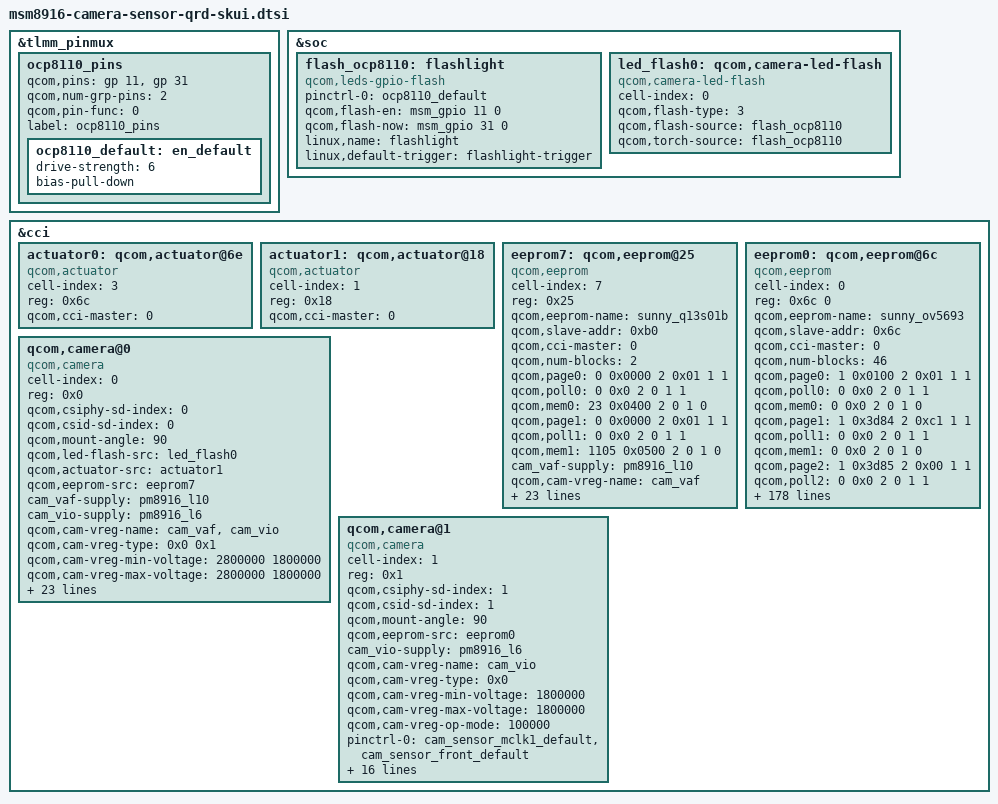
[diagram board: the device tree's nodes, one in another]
/*
 * Copyright (c) 2014, The Linux Foundation. All rights reserved.
 * Copyright (C) 2016 XiaoMi, Inc.
 *
 * This program is free software; you can redistribute it and/or modify
 * it under the terms of the GNU General Public License version 2 and
 * only version 2 as published by the Free Software Foundation.
 *
 * This program is distributed in the hope that it will be useful,
 * but WITHOUT ANY WARRANTY; without even the implied warranty of
 * MERCHANTABILITY or FITNESS FOR A PARTICULAR PURPOSE.  See the
 * GNU General Public License for more details.
 */
&tlmm_pinmux {
	ocp8110_pins {
		qcom,pins = <&gp 11> ,<&gp 31>;
		qcom,num-grp-pins = <2>;
		qcom,pin-func = <0>;
		label = "ocp8110_pins";
		ocp8110_default: en_default {
			  drive-strength = <6>;
			  bias-pull-down;
		};
	};
};

&soc {

	flash_ocp8110:flashlight {
		compatible = "qcom,leds-gpio-flash";
		status = "okay";
		pinctrl-names = "ocp8110_default";
		pinctrl-0 = <&ocp8110_default>;
		qcom,flash-en = <&msm_gpio 11 0>;
		qcom,flash-now = <&msm_gpio 31 0>;
		linux,name = "flashlight";
		linux,default-trigger = "flashlight-trigger";
	};

	led_flash0: qcom,camera-led-flash {
		cell-index = <0>;
		compatible = "qcom,camera-led-flash";
		qcom,flash-type = <3>;
		qcom,flash-source = <&flash_ocp8110>;
		qcom,torch-source = <&flash_ocp8110>;
	};
};

&cci {

	actuator0: qcom,actuator@6e {
		cell-index = <3>;
		reg = <0x6c>;
		compatible = "qcom,actuator";
		qcom,cci-master = <0>;
	};

	actuator1: qcom,actuator@18 {
		cell-index = <1>;
		reg = <0x18>;
		compatible = "qcom,actuator";
		qcom,cci-master = <0>;
	};
	eeprom7: qcom,eeprom@25 {
		cell-index = <7>;
		reg = <0x25>;
		qcom,eeprom-name = "sunny_q13s01b";
		compatible = "qcom,eeprom";
		qcom,slave-addr = <0xb0>;
		qcom,cci-master = <0>;
		qcom,num-blocks = <2>;
		qcom,page0 = <0 0x0000 2 0x01 1 1>;
		qcom,poll0 = <0 0x0 2 0 1 1>;
		qcom,mem0 = <23 0x0400 2 0 1 0>;
		qcom,page1 = <0 0x0000 2 0x01 1 1>;
		qcom,poll1 = <0 0x0 2 0 1 1>;
		qcom,mem1 = <1105 0x0500 2 0 1 0>;

		cam_vaf-supply = <&pm8916_l10>;
		qcom,cam-vreg-name = "cam_vaf";
		qcom,cam-vreg-type = <0>;
		qcom,cam-vreg-min-voltage = <2800000>;
		qcom,cam-vreg-max-voltage = <2800000>;
		qcom,cam-vreg-op-mode = <100000>;
		pinctrl-names = "cam_default", "cam_suspend";
		pinctrl-0 = <&cam_sensor_mclk0_default &cam_sensor_rear_default>;
		pinctrl-1 = <&cam_sensor_mclk0_sleep &cam_sensor_rear_sleep>;
		qcom,gpio-no-mux = <0>;
		gpios = <&msm_gpio 26 0>,
	        	<&msm_gpio 10 0>; /*This is CAM_AF_PWDM for q13s01b*/
		qcom,gpio-standby = <1>;
		qcom,gpio-req-tbl-num = <0 1>;
		qcom,gpio-req-tbl-flags = <1 0>;
		qcom,gpio-req-tbl-label = "CAMIF_MCLK","CAM_AF_PWDM";

		qcom,cam-power-seq-type = "sensor_vreg", "sensor_clk","sensor_gpio";
		qcom,cam-power-seq-val = "cam_vaf", "sensor_cam_mclk","sensor_gpio_standby";
		qcom,cam-power-seq-cfg-val = <1 23880000 1>;
		qcom,cam-power-seq-delay = <1 5 10>;
		clocks = <&clock_gcc clk_mclk0_clk_src>,<&clock_gcc clk_gcc_camss_mclk0_clk>;
		clock-names = "cam_src_clk", "cam_clk";
	};

	eeprom0: qcom,eeprom@6c {
		cell-index = <0>;
		reg = <0x6c 0>;
		qcom,eeprom-name = "sunny_ov5693";
		compatible = "qcom,eeprom";
		qcom,slave-addr = <0x6c>;
		qcom,cci-master = <0>;
		qcom,num-blocks = <46>;

		qcom,page0 = <1 0x0100 2 0x01 1 1>;
		qcom,poll0 = <0 0x0 2 0 1 1>;
		qcom,mem0 = <0 0x0 2 0 1 0>;

		/*blank0*/
		/*blank1*/
		qcom,page1 = <1 0x3d84 2 0xc1 1 1>;
		qcom,poll1 = <0 0x0 2 0 1 1>;
		qcom,mem1 = <0 0x0 2 0 1 0>;
		qcom,page2 = <1 0x3d85 2 0x00 1 1>;
		qcom,poll2 = <0 0x0 2 0 1 1>;
		qcom,mem2 = <0 0x0 2 0 1 0>;
		qcom,page3 = <1 0x3d86 2 0x0f 1 1>;
		qcom,pageen3 = <1 0x3d81 2 0x01 1 5>;
		qcom,poll3 = <0 0x0 2 0 1 1>;
		qcom,mem3 = <16 0x3d00 2 0 1 0>;

		/*blank2*/
		qcom,page4 = <1 0x3d84 2 0xc2 1 1>;
		qcom,poll4 = <0 0x0 2 0 1 1>;
		qcom,mem4 = <0 0x0 2 0 1 0>;

		qcom,page5 = <1 0x3d85 2 0x00 1 1>;
		qcom,poll5 = <0 0x0 2 0 1 1>;
		qcom,mem5 = <0 0x0 2 0 1 0>;

		qcom,page6 = <1 0x3d86 2 0x0f 1 1>;
		qcom,pageen6 = <1 0x3d81 2 0x01 1 5>;
		qcom,poll6 = <0 0x0 2 0 1 1>;
		qcom,mem6 = <16 0x3d00 2 0 1 0>;

		/*blank3*/
		qcom,page7 = <1 0x3d84 2 0xc3 1 1>;
		qcom,poll7 = <0 0x0 2 0 1 1>;
		qcom,mem7 = <0 0x0 2 0 1 0>;

		qcom,page8 = <1 0x3d85 2 0x00 1 1>;
		qcom,poll8 = <0 0x0 2 0 1 1>;
		qcom,mem8 = <0 0x0 2 0 1 0>;

		qcom,page9 = <1 0x3d86 2 0x0f 1 1>;
		qcom,pageen9 = <1 0x3d81 2 0x01 1 5>;
		qcom,poll9 = <0 0x0 2 0 1 1>;
		qcom,mem9 = <16 0x3d00 2 0 1 0>;

		/*blank4*/
		qcom,page10 = <1 0x3d84 2 0xc4 1 1>;
		qcom,poll10 = <0 0x0 2 0 1 1>;
		qcom,mem10 = <0 0x0 2 0 1 0>;

		qcom,page11 = <1 0x3d85 2 0x00 1 1>;
		qcom,poll11 = <0 0x0 2 0 1 1>;
		qcom,mem11 = <0 0x0 2 0 1 0>;

		qcom,page12 = <1 0x3d86 2 0x0f 1 1>;
		qcom,pageen12 = <1 0x3d81 2 0x01 1 5>;
		qcom,poll12 = <0 0x0 2 0 1 1>;
		qcom,mem12 = <16 0x3d00 2 0 1 0>;

		/*blank5*/
		qcom,page13 = <1 0x3d84 2 0xc5 1 1>;
		qcom,poll13 = <0 0x0 2 0 1 1>;
		qcom,mem13 = <0 0x0 2 0 1 0>;

		qcom,page14 = <1 0x3d85 2 0x00 1 1>;
		qcom,poll14 = <0 0x0 2 0 1 1>;
		qcom,mem14 = <0 0x0 2 0 1 0>;

		qcom,page15 = <1 0x3d86 2 0x0f 1 1>;
		qcom,pageen15 = <1 0x3d81 2 0x01 1 5>;
		qcom,poll15 = <0 0x0 2 0 1 1>;
		qcom,mem15 = <16 0x3d00 2 0 1 0>;

		/*blank6*/
		qcom,page16 = <1 0x3d84 2 0xc6 1 1>;
		qcom,poll16 = <0 0x0 2 0 1 1>;
		qcom,mem16 = <0 0x0 2 0 1 0>;

		qcom,page17 = <1 0x3d85 2 0x00 1 1>;
		qcom,poll17 = <0 0x0 2 0 1 1>;
		qcom,mem17 = <0 0x0 2 0 1 0>;

		qcom,page18 = <1 0x3d86 2 0x0f 1 1>;
		qcom,pageen18 = <1 0x3d81 2 0x01 1 5>;
		qcom,poll18 = <0 0x0 2 0 1 1>;
		qcom,mem18 = <16 0x3d00 2 0 1 0>;

		/*blank7*/
		qcom,page19 = <1 0x3d84 2 0xc7 1 1>;
		qcom,poll19 = <0 0x0 2 0 1 1>;
		qcom,mem19 = <0 0x0 2 0 1 0>;

		qcom,page20 = <1 0x3d85 2 0x00 1 1>;
		qcom,poll20 = <0 0x0 2 0 1 1>;
		qcom,mem20 = <0 0x0 2 0 1 0>;

		qcom,page21 = <1 0x3d86 2 0x0e 1 1>;
		qcom,pageen21 = <1 0x3d81 2 0x01 1 5>;
		qcom,poll21 = <0 0x0 2 0 1 1>;
		qcom,mem21 = <16 0x3d00 2 0 1 0>;

		/*blank8*/
		qcom,page22 = <1 0x3d84 2 0xc8 1 1>;
		qcom,poll22 = <0 0x0 2 0 1 1>;
		qcom,mem22 = <0 0x0 2 0 1 0>;

		qcom,page23 = <1 0x3d85 2 0x00 1 1>;
		qcom,poll23 = <0 0x0 2 0 1 1>;
		qcom,mem23 = <0 0x0 2 0 1 0>;

		qcom,page24 = <1 0x3d86 2 0x0f 1 1>;
		qcom,pageen24 = <1 0x3d81 2 0x01 1 5>;
		qcom,poll24 = <0 0x0 2 0 1 1>;
		qcom,mem24 = <16 0x3d00 2 0 1 0>;

		/*blank9*/
		qcom,page25 = <1 0x3d84 2 0xc9 1 1>;
		qcom,poll25 = <0 0x0 2 0 1 1>;
		qcom,mem25 = <0 0x0 2 0 1 0>;

		qcom,page26 = <1 0x3d85 2 0x00 1 1>;
		qcom,poll26 = <0 0x0 2 0 1 1>;
		qcom,mem26 = <0 0x0 2 0 1 0>;

		qcom,page27 = <1 0x3d86 2 0x0f 1 1>;
		qcom,pageen27 = <1 0x3d81 2 0x01 1 5>;
		qcom,poll27 = <0 0x0 2 0 1 1>;
		qcom,mem27 = <16 0x3d00 2 0 1 0>;

		/*blank10*/
		qcom,page28 = <1 0x3d84 2 0xca 1 1>;
		qcom,poll28 = <0 0x0 2 0 1 1>;
		qcom,mem28 = <0 0x0 2 0 1 0>;

		qcom,page29 = <1 0x3d85 2 0x00 1 1>;
		qcom,poll29 = <0 0x0 2 0 1 1>;
		qcom,mem29 = <0 0x0 2 0 1 0>;

		qcom,page30 = <1 0x3d86 2 0x0f 1 1>;
		qcom,pageen30 = <1 0x3d81 2 0x01 1 5>;
		qcom,poll30 = <0 0x0 2 0 1 1>;
		qcom,mem30 = <16 0x3d00 2 0 1 0>;

		/*blank11*/
		qcom,page31 = <1 0x3d84 2 0xcb 1 1>;
		qcom,poll31 = <0 0x0 2 0 1 1>;
		qcom,mem31 = <0 0x0 2 0 1 0>;

		qcom,page32 = <1 0x3d85 2 0x00 1 1>;
		qcom,poll32 = <0 0x0 2 0 1 1>;
		qcom,mem32 = <0 0x0 2 0 1 0>;

		qcom,page33 = <1 0x3d86 2 0x0e 1 1>;
		qcom,pageen33 = <1 0x3d81 2 0x01 1 5>;
		qcom,poll33 = <0 0x0 2 0 1 1>;
		qcom,mem33 = <16 0x3d00 2 0 1 0>;

		/*blank12*/
		qcom,page34 = <1 0x3d84 2 0xcc 1 1>;
		qcom,poll34 = <0 0x0 2 0 1 1>;
		qcom,mem34 = <0 0x0 2 0 1 0>;

		qcom,page35 = <1 0x3d85 2 0x00 1 1>;
		qcom,poll35 = <0 0x0 2 0 1 1>;
		qcom,mem35 = <0 0x0 2 0 1 0>;

		qcom,page36 = <1 0x3d86 2 0x0f 1 1>;
		qcom,pageen36 = <1 0x3d81 2 0x01 1 5>;
		qcom,poll36 = <0 0x0 2 0 1 1>;
		qcom,mem36 = <16 0x3d00 2 0 1 0>;

		/*blank13*/
		qcom,page37 = <1 0x3d84 2 0xcd 1 1>;
		qcom,poll37 = <0 0x0 2 0 1 1>;
		qcom,mem37 = <0 0x0 2 0 1 0>;

		qcom,page38 = <1 0x3d85 2 0x00 1 1>;
		qcom,poll38 = <0 0x0 2 0 1 1>;
		qcom,mem38 = <0 0x0 2 0 1 0>;

		qcom,page39 = <1 0x3d86 2 0x0f 1 1>;
		qcom,pageen39 = <1 0x3d81 2 0x01 1 5>;
		qcom,poll39 = <0 0x0 2 0 1 1>;
		qcom,mem39 = <16 0x3d00 2 0 1 0>;

		/*blank14*/
		qcom,page40 = <1 0x3d84 2 0xce 1 1>;
		qcom,poll40 = <0 0x0 2 0 1 1>;
		qcom,mem40 = <0 0x0 2 0 1 0>;

		qcom,page41 = <1 0x3d85 2 0x00 1 1>;
		qcom,poll41 = <0 0x0 2 0 1 1>;
		qcom,mem41 = <0 0x0 2 0 1 0>;

		qcom,page42 = <1 0x3d86 2 0x0f 1 1>;
		qcom,pageen42 = <1 0x3d81 2 0x01 1 5>;
		qcom,poll42 = <0 0x0 2 0 1 1>;
		qcom,mem42 = <16 0x3d00 2 0 1 0>;

		/*blank15*/
		qcom,page43 = <1 0x3d84 2 0xcf 1 1>;
		qcom,poll43 = <0 0x0 2 0 1 1>;
		qcom,mem43 = <0 0x0 2 0 1 0>;

		qcom,page44 = <1 0x3d85 2 0x00 1 1>;
		qcom,poll44 = <0 0x0 2 0 1 1>;
		qcom,mem44 = <0 0x0 2 0 1 0>;

		qcom,page45 = <1 0x3d86 2 0x0e 1 1>;
		qcom,pageen45 = <1 0x3d81 2 0x01 1 5>;
		qcom,poll45 = <0 0x0 2 0 1 1>;
		qcom,mem45 = <16 0x3d00 2 0 1 0>;

		cam_vio-supply = <&pm8916_l6>;
		cam_vana-supply = <&pm8916_l10>;
		qcom,cam-vreg-name = "cam_vio", "cam_vana";
		qcom,cam-vreg-type = <0 0>;
		qcom,cam-vreg-min-voltage = <1800000 2800000>;
		qcom,cam-vreg-max-voltage = <1800000 2800000>;
		qcom,cam-vreg-op-mode = <180000 80000>;
		pinctrl-names = "cam_default", "cam_suspend";
		pinctrl-0 = <&cam_sensor_mclk1_default &cam_sensor_front_default>;
		pinctrl-1 = <&cam_sensor_mclk1_sleep &cam_sensor_front_sleep>;

		gpios = <&msm_gpio 22 0>,
			<&msm_gpio 27 0>,
			<&msm_gpio 28 0>,
			<&msm_gpio 33 0>,
			<&msm_gpio 120 0>;
		qcom,gpio-vana = <0>;
		qcom,gpio-reset = <2>;
		qcom,gpio-standby = <3>;
		qcom,gpio-vdig = <4>;
		qcom,gpio-req-tbl-num = <0 1 2 3 4>;
		qcom,gpio-req-tbl-flags = <0 1 0 0 0>;
		qcom,gpio-req-tbl-label = "CAM_VANA",
			"CAMIF_MCLK",
			"CAM_RESET",
			"CAM_STANDBY",
			"CAM_VDIG";

		qcom,cam-power-seq-type = "sensor_vreg","sensor_gpio","sensor_vreg","sensor_gpio",
			"sensor_gpio", "sensor_gpio" , "sensor_clk";

		qcom,cam-power-seq-val = "cam_vio","sensor_gpio_vana","cam_vana","sensor_gpio_vdig",
			"sensor_gpio_reset", "sensor_gpio_standby","sensor_cam_mclk";
		qcom,cam-power-seq-cfg-val = <1 1 1 1 1 1 23880000>;
		qcom,cam-power-seq-delay = <5 5 5 5 5 5 5>;

		clocks = <&clock_gcc clk_mclk1_clk_src>,
			<&clock_gcc clk_gcc_camss_mclk1_clk>;
		clock-names = "cam_src_clk", "cam_clk";
	};


	qcom,camera@0 {
		cell-index = <0>;
		compatible = "qcom,camera";
		reg = <0x0>;
		qcom,csiphy-sd-index = <0>;
		qcom,csid-sd-index = <0>;
		qcom,mount-angle = <90>;
		qcom,led-flash-src = <&led_flash0>;
		qcom,actuator-src = <&actuator1>;
		qcom,eeprom-src = <&eeprom7>;
		cam_vaf-supply = <&pm8916_l10>;
		cam_vio-supply = <&pm8916_l6>;
		qcom,cam-vreg-name = "cam_vaf","cam_vio";
		qcom,cam-vreg-type = <0x0 0x1>;
		qcom,cam-vreg-min-voltage = <2800000 1800000>;
		qcom,cam-vreg-max-voltage = <2800000 1800000>;
		qcom,cam-vreg-op-mode = <100000 100000>;
		pinctrl-names = "cam_default", "cam_suspend";
		pinctrl-0 = <&cam_sensor_mclk0_default
				&cam_sensor_rear_default>;
		pinctrl-1 = <&cam_sensor_mclk0_sleep &cam_sensor_rear_sleep>;
		gpios = <&msm_gpio 26 0>,
			<&msm_gpio 35 0>,
			<&msm_gpio 34 0>,
			<&msm_gpio 120 0>,
			<&msm_gpio 22 0>,
			<&msm_gpio 10 0>;
		qcom,gpio-reset = <1>;
		qcom,gpio-standby = <2>;
		qcom,gpio-vdig = <3>;
		qcom,gpio-vana = <4>;
		qcom,gpio-af-pwdm = <5>;
		qcom,gpio-req-tbl-num = <0 1 2 3 4 5>;
		qcom,gpio-req-tbl-flags = <1 0 0 0 0 0>;
		qcom,gpio-req-tbl-label = "CAMIF_MCLK",
			"CAM_RESET",
			"CAM_STANDBY",
			"CAM_VDIG",
			"CAM_VANA",
			"CAM_AF_PWDM";
		qcom,sensor-position = <0>;
		qcom,sensor-mode = <0>;
		qcom,cci-master = <0>;
		status = "ok";
		clocks = <&clock_gcc clk_mclk0_clk_src>,
				<&clock_gcc clk_gcc_camss_mclk0_clk>;
		clock-names = "cam_src_clk", "cam_clk";
		qcom,mclk-23880000;
	};

	qcom,camera@1 {
		cell-index = <1>;
		compatible = "qcom,camera";
		reg = <0x1>;
		qcom,csiphy-sd-index = <1>;
		qcom,csid-sd-index = <1>;
		qcom,mount-angle = <90>;
		qcom,eeprom-src = <&eeprom0>;
		cam_vio-supply = <&pm8916_l6>;
		qcom,cam-vreg-name = "cam_vio";
		qcom,cam-vreg-type = <0x0>;
		qcom,cam-vreg-min-voltage = <1800000>;
		qcom,cam-vreg-max-voltage = <1800000>;
		qcom,cam-vreg-op-mode = <100000>;
		pinctrl-names = "cam_default", "cam_suspend";
		pinctrl-0 = <&cam_sensor_mclk1_default &cam_sensor_front_default>;
		pinctrl-1 = <&cam_sensor_mclk1_sleep &cam_sensor_front_sleep>;
		gpios = <&msm_gpio 27 0>,
			<&msm_gpio 28 0>,
			<&msm_gpio 33 0>,
			<&msm_gpio 120 0>,
			<&msm_gpio 22 0>;
		qcom,gpio-reset = <1>;
		qcom,gpio-standby = <2>;
		qcom,gpio-vdig = <3>;
		qcom,gpio-vana = <4>;
		qcom,gpio-req-tbl-num = <0 1 2 3 4>;
		qcom,gpio-req-tbl-flags = <1 0 0 0 0>;
		qcom,gpio-req-tbl-label = "CAMIF_MCLK",
			"CAM_RESET",
			"CAM_STANDBY",
			"CAM_VDIG",
			"CAM_VANA";
		qcom,cci-master = <0>;
		status = "ok";
		clocks = <&clock_gcc clk_mclk1_clk_src>,
				<&clock_gcc clk_gcc_camss_mclk1_clk>;
		clock-names = "cam_src_clk", "cam_clk";
		qcom,mclk-23880000;
	};

};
